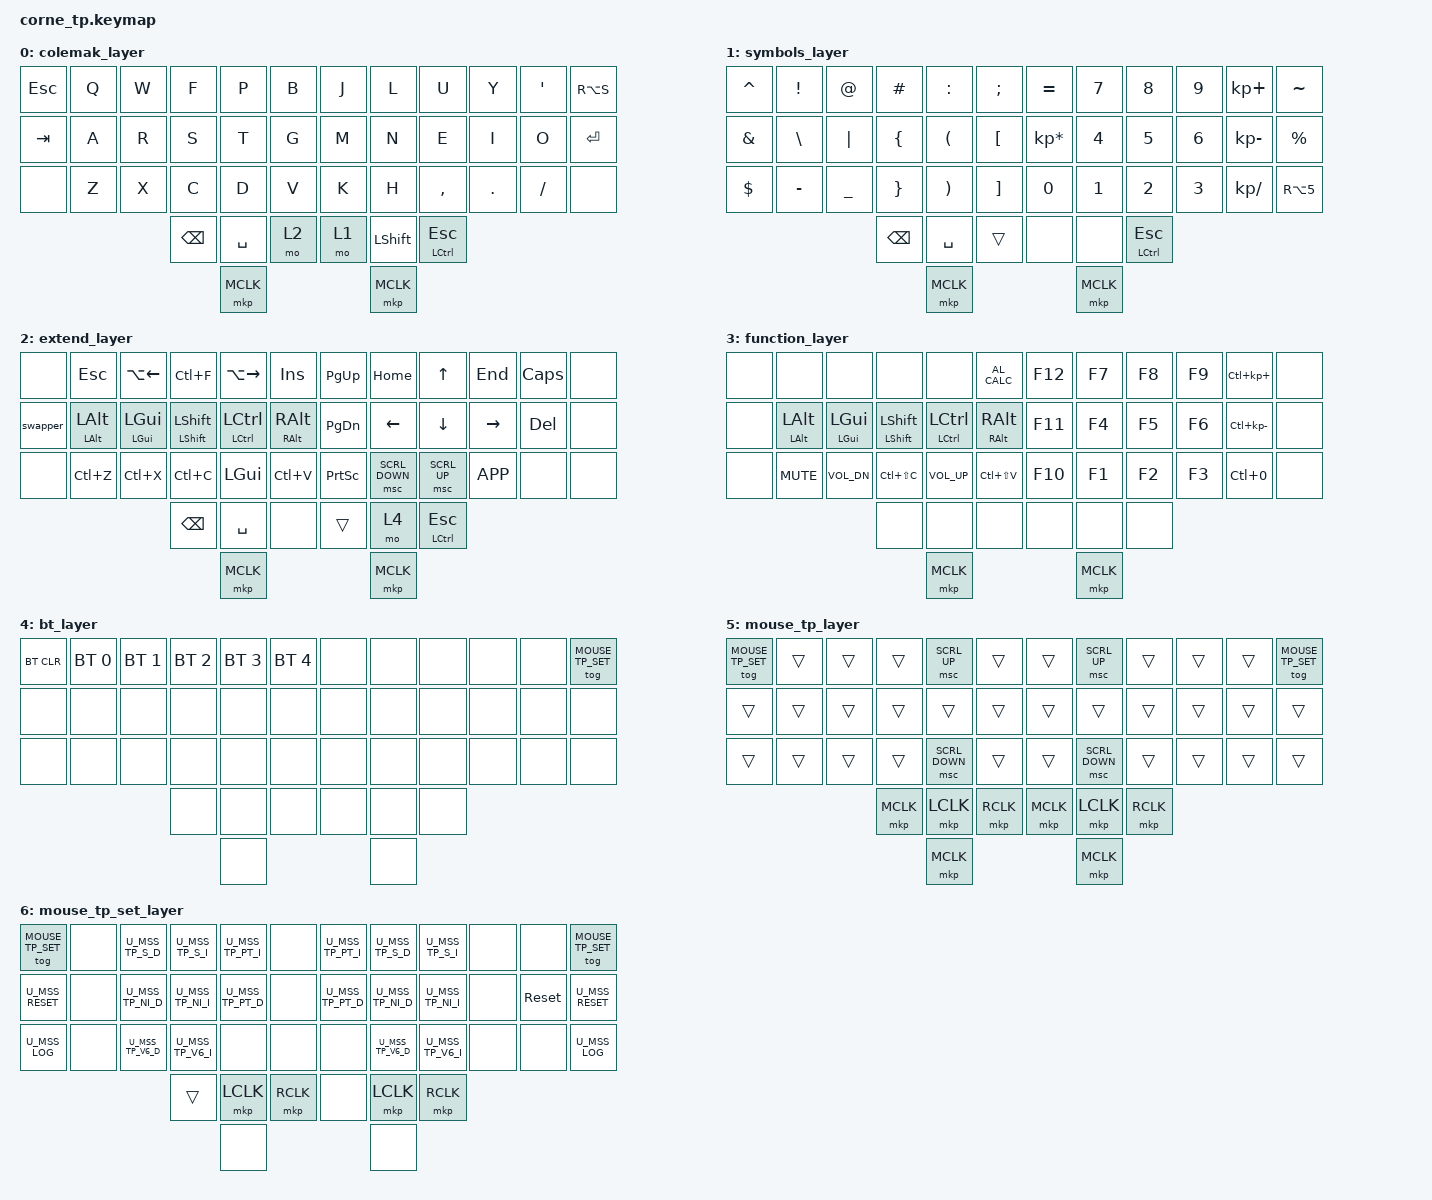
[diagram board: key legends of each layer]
/*
 * Colemak-DH layout for Corne (42 keys + 2 encoder clicks = 44 positions)
 *
 * Layer structure:
 *   0  Colemak-DH (base)
 *   1  Symbols + Numpad
 *   2  Extend (navigation)
 *   3  Function + Media        (conditional: hold L1 + L2)
 *   4  Bluetooth + TP settings entry
 *   5  Mouse / TrackPoint      (auto-activated by TP movement)
 *   6  TrackPoint settings     (runtime tuning)
 *
 * Key positions (for ignored-key-positions reference):
 *   Row 0:  0   1   2   3   4   5       6   7   8   9  10  11
 *   Row 1: 12  13  14  15  16  17      18  19  20  21  22  23
 *   Row 2: 24  25  26  27  28  29      30  31  32  33  34  35
 *   Thumb:         36  37  38              39  40  41
 *   Encoder click:               42                       43
 *
 * Encoders (one per side, A/B on D16/D10, click on D8):
 *   Left  (pos 42):  rotate = horizontal scroll, click = middle mouse
 *   Right (pos 43):  rotate = vertical scroll,   click = middle mouse
 */

#include <behaviors.dtsi>
#include <dt-bindings/zmk/keys.h>
#include <dt-bindings/zmk/bt.h>

/* Boost the scroll value baked into SCRL_UP / SCRL_DOWN / SCRL_LEFT /
 * SCRL_RIGHT from the fork's default of 10 to 50. This is the
 * community-standard fix (cf. urob/zmk-config and others) for the
 * "encoder scroll feels sluggish and lags after release" problem:
 * higher speed = the &msc input-two-axis behavior crosses its 1.0
 * accumulator threshold faster, so each press emits more wheel events
 * per millisecond. Combined with the lower tap-ms below, fast spinning
 * no longer queues up a backlog. Must be defined BEFORE the mouse.h
 * include because SCRL_* macros expand at that point. */
#define ZMK_MOUSE_DEFAULT_SCRL_VAL 50

#include <dt-bindings/zmk/mouse.h>

#define MOUSE_TP      5
#define MOUSE_TP_SET  6

#define HAS_MOUSE_TP
#include "include/mouse_tp.dtsi"

/ {
    behaviors {
        swapper: swapper {
            compatible = "zmk,behavior-tri-state";
            #binding-cells = <0>;
            bindings = <&kt LALT>, <&kp TAB>, <&kt LALT>;
            ignored-key-positions = <15>;
        };

        /* Tap = sticky modifier; hold = plain modifier (released on key release,
         * no latching). Keeps chord ergonomics via &sk while fixing the case
         * where a held mod stays latched after release (e.g. Ctrl + scroll zoom). */
        skh: sticky_or_hold {
            compatible = "zmk,behavior-hold-tap";
            #binding-cells = <2>;
            tapping-term-ms = <200>;
            flavor = "tap-preferred";
            bindings = <&kp>, <&sk>;
        };

        /* Sensor-rotate variant that drives &msc (mouse scroll) on each tick.
         * The stock inc_dec_kp only binds to &kp, so we need our own.
         *
         * tap-ms = 40: with ZMK_MOUSE_DEFAULT_SCRL_VAL bumped to 50, each
         * 16 ms tick of the &msc input-two-axis behavior adds
         *   move = speed * 16 / 1000 = 50 * 0.016 = 0.80
         * to its fractional accumulator. The integer threshold (1.0) is
         * crossed every 2 ticks → one wheel event per ~32 ms. A 40 ms
         * tap-ms covers that with a small margin and emits 1 wheel event
         * per detent. Crucially, the behavior_queue can drain queued
         * trigger pairs every 40 ms instead of every 130 ms, so spinning
         * the encoder fast no longer produces a multi-second scroll tail
         * after the user stops. */
        inc_dec_msc: inc_dec_msc {
            compatible = "zmk,behavior-sensor-rotate-var";
            #sensor-binding-cells = <2>;
            bindings = <&msc>, <&msc>;
            tap-ms = <40>;
        };
    };

    conditional_layers {
        compatible = "zmk,conditional-layers";
        function_layer_combo {
            if-layers = <1 2>;
            then-layer = <3>;
        };
    };

    keymap {
        compatible = "zmk,keymap";

        /* Layer 0: Colemak-DH
         * ┌─────┬─────┬─────┬─────┬─────┬─────┐   ┌─────┬─────┬─────┬─────┬─────┬─────┐
         * │ ESC │  Q  │  W  │  F  │  P  │  B  │   │  J  │  L  │  U  │  Y  │  '  │RA(S)│
         * ├─────┼─────┼─────┼─────┼─────┼─────┤   ├─────┼─────┼─────┼─────┼─────┼─────┤
         * │ TAB │  A  │  R  │  S  │  T  │  G  │   │  M  │  N  │  E  │  I  │  O  │ RET │
         * ├─────┼─────┼─────┼─────┼─────┼─────┤   ├─────┼─────┼─────┼─────┼─────┼─────┤
         * │     │  Z  │  X  │  C  │  D  │  V  │   │  K  │  H  │  ,  │  .  │  /  │     │
         * └─────┴─────┴─────┼─────┼─────┼─────┤   ├─────┼─────┼─────┼─────┴─────┴─────┘
         *                   │BSPC │ SPC │ L2  │   │ L1  │LSHFT│CT/ES│
         *                   └─────┴─────┴─────┘   └─────┴─────┴─────┘
         *  Encoders:    L click: MCLK     R click: MCLK
         */
        colemak_layer {
            bindings = <
                &kp ESC    &kp Q  &kp W  &kp F      &kp P      &kp B      &kp J  &kp L      &kp U      &kp Y    &kp SQT   &kp RA(S)
                &kp TAB    &kp A  &kp R  &kp S      &kp T      &kp G      &kp M  &kp N      &kp E      &kp I    &kp O     &kp RET
                &none      &kp Z  &kp X  &kp C      &kp D      &kp V      &kp K  &kp H      &kp COMMA  &kp DOT  &kp FSLH  &none
                                         &kp BSPC   &kp SPACE  &mo 2      &mo 1  &kp LSHFT  &mt LCTRL ESC
                                                       &mkp MCLK              &mkp MCLK
            >;
            sensor-bindings = <&inc_dec_msc SCRL_RIGHT SCRL_LEFT
                               &inc_dec_msc SCRL_DOWN  SCRL_UP>;
        };

        /* Layer 1: Symbols + Numpad
         * ┌─────┬─────┬─────┬─────┬─────┬─────┐   ┌─────┬─────┬─────┬─────┬─────┬─────┐
         * │  ^  │  !  │  @  │  #  │  :  │  ;  │   │  =  │  7  │  8  │  9  │ KP+ │  ~  │
         * ├─────┼─────┼─────┼─────┼─────┼─────┤   ├─────┼─────┼─────┼─────┼─────┼─────┤
         * │  &  │  \  │  |  │  {  │  (  │  [  │   │ KP* │  4  │  5  │  6  │ KP- │  %  │
         * ├─────┼─────┼─────┼─────┼─────┼─────┤   ├─────┼─────┼─────┼─────┼─────┼─────┤
         * │  $  │  -  │  _  │  }  │  )  │  ]  │   │  0  │  1  │  2  │  3  │ KP/ │RA(5)│
         * └─────┴─────┴─────┼─────┼─────┼─────┤   ├─────┼─────┼─────┼─────┴─────┴─────┘
         *                   │BSPC │ SPC │[L2] │   │     │     │CT/ES│
         *                   └─────┴─────┴─────┘   └─────┴─────┴─────┘
         */
        symbols_layer {
            bindings = <
                &kp CARET  &kp EXCL   &kp AT     &kp HASH   &kp COLON  &kp SEMI    &kp EQUAL        &kp N7  &kp N8  &kp N9  &kp KP_PLUS    &kp TILDE
                &kp AMPS   &kp BSLH   &kp PIPE   &kp LBRC   &kp LPAR   &kp LBKT    &kp KP_MULTIPLY  &kp N4  &kp N5  &kp N6  &kp KP_MINUS   &kp PRCNT
                &kp DLLR   &kp MINUS  &kp UNDER  &kp RBRC   &kp RPAR   &kp RBKT    &kp N0           &kp N1  &kp N2  &kp N3  &kp KP_DIVIDE  &kp RA(N5)
                                                  &kp BSPC   &kp SPACE  &trans      &none            &none   &mt LCTRL ESC
                                                       &mkp MCLK              &mkp MCLK
            >;
            sensor-bindings = <&inc_dec_msc SCRL_RIGHT SCRL_LEFT
                               &inc_dec_msc SCRL_DOWN  SCRL_UP>;
        };

        /* Layer 2: Extend / Navigation
         * ┌─────┬─────┬─────┬─────┬─────┬─────┐   ┌─────┬─────┬─────┬─────┬─────┬─────┐
         * │     │ ESC │A(←) │ C-F │A(→) │ INS │   │PG_UP│HOME │  UP │ END │CAPS │     │
         * ├─────┼─────┼─────┼─────┼─────┼─────┤   ├─────┼─────┼─────┼─────┼─────┼─────┤
         * │ SWAP│ ALT │ GUI │SHIFT│CTRL │ALTGR│   │PG_DN│LEFT │DOWN │RIGHT│ DEL │     │
         * ├─────┼─────┼─────┼─────┼─────┼─────┤   ├─────┼─────┼─────┼─────┼─────┼─────┤
         * │     │UNDO │ CUT │COPY │ GUI │PASTE│   │PSCRN│SCR_D│SCR_U│ APP │     │     │
         * └─────┴─────┴─────┼─────┼─────┼─────┤   ├─────┼─────┼─────┼─────┴─────┴─────┘
         *                   │BSPC │ SPC │     │   │[L1] │ MO4 │CT/ES│
         *                   └─────┴─────┴─────┘   └─────┴─────┴─────┘
         *  SWAP = Alt-Tab swapper
         */
        extend_layer {
            bindings = <
                &none     &kp ESC    &kp LA(LEFT)  &kp LC(F)   &kp LA(RIGHT)  &kp INS     &kp PG_UP  &kp HOME  &kp UP    &kp END    &kp CAPS  &none
                &swapper  &skh LALT LALT  &skh LGUI LGUI  &skh LSHFT LSHFT  &skh LCTRL LCTRL  &skh RALT RALT    &kp PG_DN  &kp LEFT  &kp DOWN  &kp RIGHT  &kp DEL   &none
                &none     &kp LC(Z)  &kp LC(X)     &kp LC(C)   &kp LGUI       &kp LC(V)   &kp PSCRN  &msc SCRL_DOWN &msc SCRL_UP &kp K_APP  &none     &none
                                                    &kp BSPC   &kp SPACE      &none       &trans     &mo 4     &mt LCTRL ESC
                                                       &mkp MCLK              &mkp MCLK
            >;
            sensor-bindings = <&inc_dec_msc SCRL_RIGHT SCRL_LEFT
                               &inc_dec_msc SCRL_DOWN  SCRL_UP>;
        };

        /* Layer 3: Function + Media (conditional: L1 + L2)
         * ┌─────┬─────┬─────┬─────┬─────┬─────┐   ┌─────┬─────┬─────┬─────┬─────┬─────┐
         * │     │     │     │     │     │CALC │   │ F12 │ F7  │ F8  │ F9  │C-KP+│     │
         * ├─────┼─────┼─────┼─────┼─────┼─────┤   ├─────┼─────┼─────┼─────┼─────┼─────┤
         * │     │ ALT │ GUI │SHIFT│CTRL │ALTGR│   │ F11 │ F4  │ F5  │ F6  │C-KP-│     │
         * ├─────┼─────┼─────┼─────┼─────┼─────┤   ├─────┼─────┼─────┼─────┼─────┼─────┤
         * │     │MUTE │VOL_D│CS-C │VOL_U│CS-V │   │ F10 │ F1  │ F2  │ F3  │ C-0 │     │
         * └─────┴─────┴─────┼─────┼─────┼─────┤   ├─────┼─────┼─────┼─────┴─────┴─────┘
         *                   │     │     │     │   │     │     │     │
         *                   └─────┴─────┴─────┘   └─────┴─────┴─────┘
         */
        function_layer {
            bindings = <
                &none  &none       &none          &none          &none         &kp C_AL_CALC    &kp F12  &kp F7  &kp F8  &kp F9  &kp LC(KP_PLUS)   &none
                &none  &skh LALT LALT  &skh LGUI LGUI  &skh LSHFT LSHFT  &skh LCTRL LCTRL  &skh RALT RALT    &kp F11  &kp F4  &kp F5  &kp F6  &kp LC(KP_MINUS)  &none
                &none  &kp C_MUTE  &kp C_VOL_DN   &kp LC(LS(C))  &kp C_VOL_UP  &kp LC(LS(V))    &kp F10  &kp F1  &kp F2  &kp F3  &kp LC(N0)        &none
                                                   &none          &none         &none            &none    &none   &none
                                                       &mkp MCLK              &mkp MCLK
            >;
            sensor-bindings = <&inc_dec_kp C_VOL_UP C_VOL_DN
                               &inc_dec_kp C_NEXT  C_PREV>;
        };

        /* Layer 4: Bluetooth + TP-settings entry
         * ┌─────┬─────┬─────┬─────┬─────┬─────┐   ┌─────┬─────┬─────┬─────┬─────┬─────┐
         * │BTCLR│ BT0 │ BT1 │ BT2 │ BT3 │ BT4 │   │     │     │     │     │     │TPSET│
         * ├─────┼─────┼─────┼─────┼─────┼─────┤   ├─────┼─────┼─────┼─────┼─────┼─────┤
         * │     │     │     │     │     │     │   │     │     │     │     │     │     │
         * ├─────┼─────┼─────┼─────┼─────┼─────┤   ├─────┼─────┼─────┼─────┼─────┼─────┤
         * │     │     │     │     │     │     │   │     │     │     │     │     │     │
         * └─────┴─────┴─────┼─────┼─────┼─────┤   ├─────┼─────┼─────┼─────┴─────┴─────┘
         *                   │     │     │     │   │     │     │     │
         *                   └─────┴─────┴─────┘   └─────┴─────┴─────┘
         */
        bt_layer {
            bindings = <
                &bt BT_CLR  &bt BT_SEL 0  &bt BT_SEL 1  &bt BT_SEL 2  &bt BT_SEL 3  &bt BT_SEL 4    &none  &none  &none  &none  &none  &tog MOUSE_TP_SET
                &none       &none         &none         &none         &none         &none           &none  &none  &none  &none  &none  &none
                &none       &none         &none         &none         &none         &none           &none  &none  &none  &none  &none  &none
                                                        &none         &none         &none           &none  &none  &none
                                                       &none                  &none
            >;
            sensor-bindings = <&inc_dec_msc SCRL_RIGHT SCRL_LEFT
                               &inc_dec_msc SCRL_DOWN  SCRL_UP>;
        };

        /* Layer 5: Mouse / TrackPoint (auto-activated by TP motion)
         * Click keys on the thumb cluster, scroll on the home-row index for
         * vertical-scroll-via-keys when the encoder is not reachable.
         * ┌─────┬─────┬─────┬─────┬─────┬─────┐   ┌─────┬─────┬─────┬─────┬─────┬─────┐
         * │TPSET│     │     │     │SCRLU│     │   │     │SCRLU│     │     │     │TPSET│
         * ├─────┼─────┼─────┼─────┼─────┼─────┤   ├─────┼─────┼─────┼─────┼─────┼─────┤
         * │     │     │     │     │     │     │   │     │     │     │     │     │     │
         * ├─────┼─────┼─────┼─────┼─────┼─────┤   ├─────┼─────┼─────┼─────┼─────┼─────┤
         * │     │     │     │     │SCRLD│     │   │     │SCRLD│     │     │     │     │
         * └─────┴─────┴─────┼─────┼─────┼─────┤   ├─────┼─────┼─────┴─────┴─────┘
         *                   │ MCLK│ LCLK│ RCLK│   │ MCLK│ LCLK│ RCLK│
         *                   └─────┴─────┴─────┘   └─────┴─────┴─────┘
         */
        mouse_tp_layer {
            bindings = <
                &tog MOUSE_TP_SET  &trans  &trans  &trans  &msc SCRL_UP    &trans      &trans       &msc SCRL_UP    &trans  &trans  &trans  &tog MOUSE_TP_SET
                &trans             &trans  &trans  &trans  &trans          &trans      &trans       &trans          &trans  &trans  &trans  &trans
                &trans             &trans  &trans  &trans  &msc SCRL_DOWN  &trans      &trans       &msc SCRL_DOWN  &trans  &trans  &trans  &trans
                                                   &mkp MCLK  &mkp LCLK  &mkp RCLK    &mkp MCLK    &mkp LCLK  &mkp RCLK
                                                       &mkp MCLK              &mkp MCLK
            >;
            sensor-bindings = <&inc_dec_msc SCRL_RIGHT SCRL_LEFT
                               &inc_dec_msc SCRL_DOWN  SCRL_UP>;
        };

        /* Layer 6: TrackPoint runtime tuning
         * ┌─────┬─────┬─────┬─────┬─────┬─────┐   ┌─────┬─────┬─────┬─────┬─────┬─────┐
         * │TPSET│     │SENS-│SENS+│PTS+ │     │   │PTS+ │SENS-│SENS+│     │     │TPSET│
         * ├─────┼─────┼─────┼─────┼─────┼─────┤   ├─────┼─────┼─────┼─────┼─────┼─────┤
         * │RESET│     │ NI- │ NI+ │PTS- │     │   │PTS- │ NI- │ NI+ │     │RCAL │RESET│
         * ├─────┼─────┼─────┼─────┼─────┼─────┤   ├─────┼─────┼─────┼─────┼─────┼─────┤
         * │ LOG │     │ V6- │ V6+ │     │     │   │     │ V6- │ V6+ │     │     │ LOG │
         * └─────┴─────┴─────┼─────┼─────┼─────┤   ├─────┼─────┼─────┼─────┴─────┴─────┘
         *                   │     │ LCLK│ RCLK│   │     │ LCLK│ RCLK│
         *                   └─────┴─────┴─────┘   └─────┴─────┴─────┘
         *  TPSET = toggle out of this layer (top corners on both sides)
         *  SENS  = sensitivity (U_MSS_TP_S_*)
         *  V6    = transfer-function upper plateau / max accel (U_MSS_TP_V6_*)
         *  NI    = negative inertia, fights post-release drift (U_MSS_TP_NI_*)
         *  PTS   = press-to-select threshold (U_MSS_TP_PT_*) — only effective
         *          if `tp-press-to-select;` is enabled in DT (it isn't here)
         *  RESET = wipe flash settings + restore TP firmware defaults
         *  RCAL  = recalibrate TP via &sys_reset: tap with hand OFF the TP to
         *          re-zero the strain-gauge baseline (settings preserved;
         *          costs a ~3 s BT reconnect while the central reboots)
         *  LOG   = dump current &mouse_ps2 { ... } block to USB serial
         *  LCLK / RCLK on the thumbs are left/right mouse buttons; the encoders
         *  are intentionally inert on this layer.
         */
        mouse_tp_set_layer {
            bindings = <
                &tog MOUSE_TP_SET  &none  U_MSS_TP_S_D   U_MSS_TP_S_I   U_MSS_TP_PT_I  &none      U_MSS_TP_PT_I  U_MSS_TP_S_D   U_MSS_TP_S_I   &none  &none  &tog MOUSE_TP_SET
                U_MSS_RESET        &none  U_MSS_TP_NI_D  U_MSS_TP_NI_I  U_MSS_TP_PT_D  &none      U_MSS_TP_PT_D  U_MSS_TP_NI_D  U_MSS_TP_NI_I  &none  &sys_reset  U_MSS_RESET
                U_MSS_LOG          &none  U_MSS_TP_V6_D  U_MSS_TP_V6_I  &none          &none      &none          U_MSS_TP_V6_D  U_MSS_TP_V6_I  &none  &none  U_MSS_LOG
                                                          &trans         &mkp LCLK      &mkp RCLK  &none          &mkp LCLK      &mkp RCLK
                                                       &none                  &none
            >;
            sensor-bindings = <&inc_dec_msc SCRL_RIGHT SCRL_LEFT
                               &inc_dec_msc SCRL_DOWN  SCRL_UP>;
        };
    };
};
